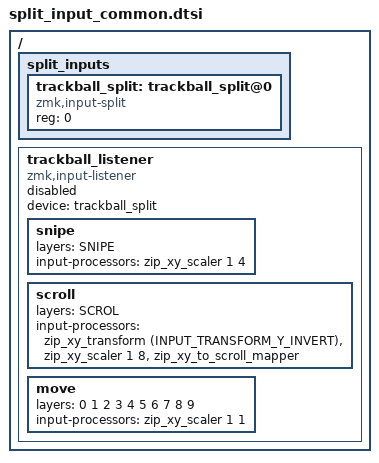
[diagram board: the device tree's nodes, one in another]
#include <dt-bindings/zmk/input_transform.h>
#include <input/processors.dtsi>

#define DEFAU 0
#define WINDO 1
#define GAMIN 2
#define NUMBE 3
#define SYMBO 4
#define LOGAM 5
#define SUPER 6
#define MOUSE 7
#define TILIN 8
#define TILWI 9
#define SCROL 10
#define SNIPE 11

/ {
  split_inputs {
    #address-cells = <1>;
    #size-cells = <0>;

    trackball_split: trackball_split@0 {
      compatible = "zmk,input-split";
      reg = <0>;
    };
  };

  trackball_listener: trackball_listener {
    compatible = "zmk,input-listener";
    status = "disabled";
    device = <&trackball_split>;

    snipe {
      layers = <SNIPE>;
      input-processors = <&zip_xy_scaler 1 4>;
    };

    scroll {
      layers = <SCROL>;
      input-processors = <&zip_xy_transform (INPUT_TRANSFORM_Y_INVERT)>, <&zip_xy_scaler 1 8>, <&zip_xy_to_scroll_mapper>;
    };

    move {
      layers = <0 1 2 3 4 5 6 7 8 9>;
      input-processors = <&zip_xy_scaler 1 1>;
    };
  };

};

